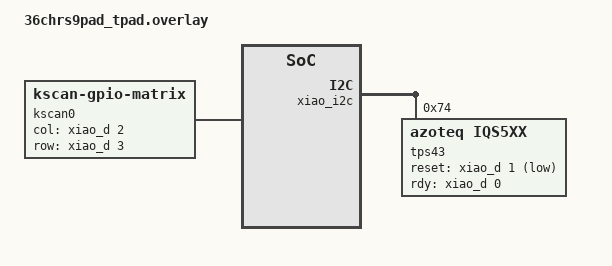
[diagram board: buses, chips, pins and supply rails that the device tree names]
/*
 * Copyright (c) 2020 The ZMK Contributors
 *
 * SPDX-License-Identifier: MIT
 */

#include "36chrs9pad.dtsi" 
#include <dt-bindings/zmk/matrix_transform.h>
#include <dt-bindings/zmk/input_transform.h>
#include <input/processors.dtsi>

&default_transform {
	col-offset = <0>;
}; 

/ {
    kscan0: kscan {
        compatible = "zmk,kscan-gpio-matrix";
        diode-direction = "col2row";
    col-gpios//without shift register, direct to pins
        = <&xiao_d 2 GPIO_ACTIVE_HIGH>  //Col0
        ;
	row-gpios
        = <&xiao_d 3 (GPIO_ACTIVE_HIGH | GPIO_PULL_DOWN)>//Row2
        ;
    };
};
/{
    tps43_input: tps43_input {
        compatible = "zmk,input-listener";
        device = <&tps43>;
    };
};

&xiao_i2c {
    status = "okay";
    tps43: iqs5xx@74 {
        status = "okay";
        compatible = "azoteq,iqs5xx";
        reg = <0x74>;

        reset-gpios = <&xiao_d 1 GPIO_ACTIVE_LOW>;
        rdy-gpios = <&xiao_d 0 GPIO_ACTIVE_HIGH>;

        /*
         * Potentially non-exhaustive list of configuration options.
         * See: dts/bindings/input/azoteq,iqs5xx-common.yaml for a full list.
         */
        one-finger-tap;
        press-and-hold;
        press-and-hold-time = <250>;
        two-finger-tap;

        scroll;
        natural-scroll-y;
        natural-scroll-x;

        bottom-beta = <5>;
        stationary-threshold = <5>;

        // switch-xy;
    };
};
